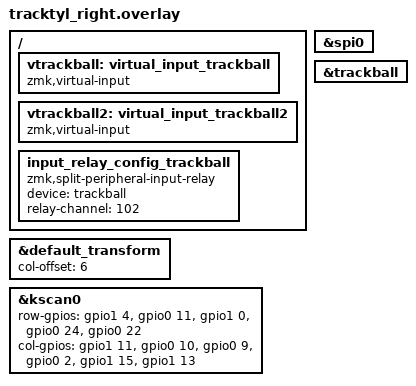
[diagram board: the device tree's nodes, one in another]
#include "tracktyl.dtsi"
#include "tracktyl_3610.dtsi"

&default_transform { // The matrix transform for this board is 6 columns over because the left half is 6 columns wide according to the matrix.
    col-offset = <6>;
};

&kscan0 {
        

        row-gpios
             = <&gpio1 4 (GPIO_ACTIVE_HIGH | GPIO_PULL_DOWN)>
            , <&gpio0 11 (GPIO_ACTIVE_HIGH | GPIO_PULL_DOWN)>
            , <&gpio1 0 (GPIO_ACTIVE_HIGH | GPIO_PULL_DOWN)>
            , <&gpio0 24 (GPIO_ACTIVE_HIGH | GPIO_PULL_DOWN)>
            , <&gpio0 22 (GPIO_ACTIVE_HIGH | GPIO_PULL_DOWN)>
            ;
        col-gpios
            = <&gpio1 11 GPIO_ACTIVE_HIGH>
            , <&gpio0 10 GPIO_ACTIVE_HIGH>
            , <&gpio0 9 GPIO_ACTIVE_HIGH>
            , <&gpio0 2 GPIO_ACTIVE_HIGH>
            , <&gpio1 15 GPIO_ACTIVE_HIGH>
            , <&gpio1 13 GPIO_ACTIVE_HIGH>
            ;
};

&spi0 {
    status = "okay";
};

&trackball {
    status = "okay";
};

/ {
	vtrackball: virtual_input_trackball {
		compatible = "zmk,virtual-input";
	};
	vtrackball2: virtual_input_trackball2 {
		compatible = "zmk,virtual-input";
	};

	input_relay_config_trackball {
		compatible = "zmk,split-peripheral-input-relay";
		device = <&trackball>;
		relay-channel = <102>;
	};
};
